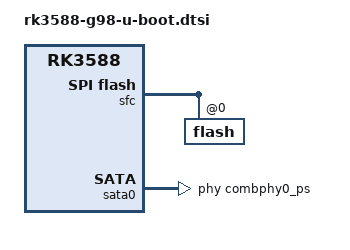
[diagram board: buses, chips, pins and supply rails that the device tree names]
// SPDX-License-Identifier: (GPL-2.0+ OR MIT)

#include "rk3588-u-boot.dtsi"

&sfc {
	bootph-pre-ram;

	flash@0 {
		bootph-pre-ram;
		bootph-some-ram;
	};
};

&sata0 {
	phys = <&combphy0_ps PHY_TYPE_SATA>;
	phy-names = "sata-phy";
};

&uart2 {
	bootph-pre-ram;
};
